# AE722F80F55D5LS_CM55_HE_View register map
Vendor: Alif Semiconductor; Series: E7; File version: 1.0
CPU: CM55 r1p0, selectable endian, MPU, FPU, double-precision FPU, DSP, VTOR, 8 interrupt priority bits, 1 SAU regions
Registers are 32-bit, read-write, reset 0x0 unless marked. A register's access mark holds for its fields unless they carry their own. Offsets are from the block's base; [hi:lo] are bit positions; {n}, {i} and the like mark numbered series.

## LPSPI
Base 0x43000000
Same registers: SPI0 0x48103000, SPI1 0x48104000, SPI2 0x48105000, SPI3 0x48106000
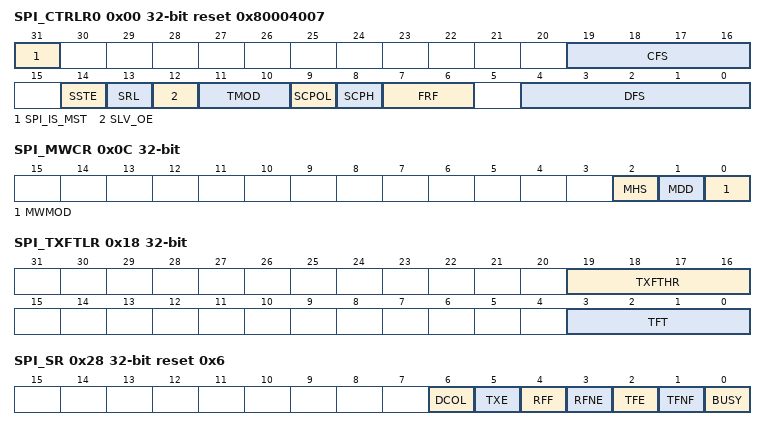
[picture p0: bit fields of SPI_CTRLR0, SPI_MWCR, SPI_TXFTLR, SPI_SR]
0x00 SPI_CTRLR0 reset 0x80004007 — Control Register 0
  [31] SPI_IS_MST — This bit selects if the SPI is working in Master or Slave mode.
    0=SPI is Slave; 1=SPI is Master
  [19:16] CFS — Control Frame Size. Selects the length of the control word for the Microwire frame format.
    {v}={v+1:02}-bit Control Word (v=0..15)
  [14] SSTE — Slave Select Toggle Enable. While operating in SPI mode with clock phase (SCPH) set to 0x0, this bit controls the behavior of the slave select line between data frames.
    0=The slave select line will stay low and SPI_SCLK will run continuously for the duration of the transfer; 1=The slave select line will toggle between consecutive data frames, with the serial clock (SPI_SCLK) being held to its default value while the slave select line is high
  [13] SRL — Shift Register Loop. Used for testing purposes only. When internally active, connects the transmit shift register output to the receive shift register input. Can be used in both serial slave and serial Master mode. When the SPI is configured as a slave in loopback mode, the slave select input and SPI_CLK signals must be provided by an external source. In this mode, the slave cannot generate these signals because there is nothing to which to loop back.
    0=Normal Mode Operation; 1=Test Mode Operation
  [12] SLV_OE — Slave Output Enable. Relevant only when the SPI is configured as a serial slave device. When configured as a serial master, this bit has no functionality. This bit enables or disables the setting of the output enable signal from the SPI serial slave. When the SLV_OE = 0x1, the output enable signal can never be active. When the output enable signal controls the tri-state buffer on the TXD output from the slave, a high impedance state is always present on the slave TXD output when the SLV_OE bit is set to 0x1. This is useful when the master transmits in broadcast mode (master transmits data to all slave devices). Only one slave may respond with data on the master RXD line. This bit is enabled after reset and must be disabled by software (when broadcast mode is used), if the device has no need to respond with data.
    0=Slave output is enabled; 1=Slave output is disabled
  [11:10] TMOD — Transfer Mode. Selects the mode of transfer for serial communication. This field does not affect the transfer duplicity. Only indicates whether the receive or transmit data are valid. In Transmit Only mode, data received from the external device is not valid and is not stored in the receive FIFO memory; it is overwritten on the next transfer. In Receive Only mode, transmitted data are not valid. After the first write to the transmit FIFO, the same word is retransmitted for the duration of the transfer. In Transmit and Receive mode, both transmit and receive data are valid. The transfer continues until the transmit FIFO is empty. Data received from the external device are stored into the receive FIFO memory, where it can be accessed by the host processor.
    0=Transmit and Receive; 1=Transmit Only mode; 2=Receive Only mode; 3=EEPROM Read mode
  [9] SCPOL — Serial Clock Polarity. Valid when the Frame Format (FRF) bit is set to Motorola SPI. Used to select the polarity of the inactive serial clock, which is held inactive when the SPI master is not actively transferring data on the serial bus.
    0=Inactive state of serial clock is low; 1=Inactive state of serial clock is high
  [8] SCPH — Serial Clock Phase. Valid when the FRF bit is set to Motorola SPI. The serial clock phase selects the relationship of the serial clock with the slave select signal. When SCPH = 0, data are captured on the first edge of the serial clock. When SCPH = 1, the serial clock starts toggling one cycle after the slave select line is activated, and data are captured on the second edge of the serial clock.
    0=Serial clock toggles in middle of first bit; 1=Serial clock toggles at start of first bit
  [7:6] FRF — Frame Format. Selects which serial protocol transfers the data.
    0=Motorola SPI frame format; 1=Texas Instruments SSP frame format; 2=National Semiconductors Microwire frame format
  [4:0] DFS — Data Frame Size. Selects the data frame length. When the data frame size is programmed to be less than 32 bits, the receive data is automatically right-justified by the receive logic, with the upper bits of the receive FIFO zero-padded. User must right-justify transmit data before writing into the transmit FIFO. The transmit logic ignores the upper unused bits when transmitting the data.
    {v}={v+1:02}-bit serial data transfer (v=3..31)
0x04 SPI_CTRLR1 — Control Register 1
  [15:0] NDF — Number of Data Frames. When the SPI_CTRLR0[TMOD] = 0x2 or SPI_CTRLR0[TMOD] = 0x3, this bit field sets the number of data frames to be continuously received by the SPI. The SPI continues to receive serial data until the number of data frames received is equal to this register value plus 1, which enables the user to receive up to 64KB of data in a continuous transfer. When the SPI is configured as a serial slave, the transfer continues for as long as the slave is selected. Therefore, this bit field serves no purpose and is not present when the SPI is configured as a serial slave.
0x08 SPI_ENR — SPI Enable Register
  [0] SPI_EN — SPI Enable. Enables and disables all SPI operations. When disabled, all serial transfers are halted immediately. Transmit and receive FIFO buffers are cleared when the device is disabled. It is impossible to program some of the SPI control registers when enabled. When disabled, the SPI sleep output is set (after delay) to inform the system that it is safe to remove the SPI_CLK, thus saving power consumption in the system.
    0=Disables SPI; 1=Enables SPI
0x0C SPI_MWCR — Microwire Control Register
  [2] MHS — Microwire Handshaking. Relevant only when the SPI is configured as a serial master device. When configured as a serial slave, this bit has no functionality. Used to enable and disable the busy/ready handshaking interface for the Microwire protocol. When enabled, the SPI checks for a ready status from the target slave, after the transfer of the last data/control bit, before clearing the BUSY status in the SPI_SR[BUSY] bit.
    0=Handshaking interface is disabled; 1=Handshaking interface is enabled
  [1] MDD — Microwire Control. Defines the direction of the data word when the Microwire serial protocol is used. When this bit is set to 0, the data word is received by the SPI module from the external serial device. When this bit is set to 1, the data word is transmitted from the SPI module to the external serial device.
    0=SPI receives data; 1=SPI transmits data
  [0] MWMOD — Microwire Transfer Mode. Defines whether the Microwire transfer is sequential or non-sequential. When sequential mode is used, only one control word is needed to transmit or receive a block of data words. When non-sequential mode is used, there must be a control word for each data word that is transmitted or received.
    0=Non-Sequential Transfer; 1=Sequential Transfer
0x10 SPI_SER reset 0x1 — Slave Enable Register
  [3:0] SER — Slave Select Enable Flag. Each bit in this bit field corresponds to a slave select line from the SPI master. When a bit in this bit field is set to 0x1, the corresponding slave select line from the master is activated when a serial transfer begins. It should be noted that setting or clearing bits in this bit field have no effect on the corresponding slave select outputs until a transfer is started. Before beginning a transfer, user should enable the bit in this field that corresponds to the slave device with which the master wants to communicate. When not operating in broadcast mode, only one bit in this field should be set.
    0=Not Selected; 1=Selected
0x14 SPI_BAUDR — Baud Rate Select Register
  [15:1] SCKDV — SPI Clock Divider. This field contains the MSB 15 bits of the 16-bit SPI_CLK divider value. The LSB for SPI_CLK divider is always set to 0 and is unaffected by a write operation, which ensures the divider is always set to an even value. If this field is set to all 0s, the serial output clock (SPI_SCLK) is disabled. The frequency of the SPI_SCLK is derived from the following equation: FSPI_SCLK = FSPI_CLK/BAUDR Where BAUDR is any even value between 2 and 65534, and BAUDR = SCKDV x 2. For example, for FSPI_CLK = 3.6864 MHz and SCKDV = 1b'1: BAUDR = 2 and FSPI_SCLK= 3.6864/2 = 1.8432 MHz. For more information, see Section SPI Clock Ratios.
0x18 SPI_TXFTLR — Transmit FIFO Threshold Level Register
  [19:16] TXFTHR — Transfer Start FIFO Level. Used to control the level of entries in transmit FIFO above which transfer will start on serial line. This bit field is used to ensure that sufficient data is present in transmit FIFO before starting a write operation on serial line. These field is valid only for Master mode of operation. Note: This field is functional only for SPI module. It is not functional for LPSPI module.
  [3:0] TFT — Transmit FIFO Threshold. Controls the level of entries (or below) at which the transmit FIFO controller triggers an interrupt. The FIFO depth is 16. If the value in this bit field is set greater than or equal to the depth of the FIFO, this bit field is not written and retains its current value. When the number of transmit FIFO entries is less than or equal to this value, the transmit FIFO empty interrupt is triggered.
0x1C SPI_RXFTLR — Receive FIFO Threshold Level Register
  [3:0] RFT — Receive FIFO Threshold. Controls the level of entries (or above) at which the receive FIFO controller triggers an interrupt. The FIFO depth is 16. If the value in this bit field is set greater than the depth of the FIFO, this bit field is not written and retains its current value. When the number of receive FIFO entries is greater than or equal to this value + 1, the receive FIFO full interrupt is triggered.
0x20 SPI_TXFLR ro — Transmit FIFO Level Register
  [4:0] TXTFL — Transmit FIFO Level. Contains the number of valid data entries in the transmit FIFO.
0x24 SPI_RXFLR ro — Receive FIFO Level Register
  [4:0] RXTFL — Receive FIFO Level. Contains the number of valid data entries in the receive FIFO.
0x28 SPI_SR ro reset 0x6 — Status Register
  [6] DCOL — Data Collision Error. Relevant only when the SPI is configured as a master device. This bit is set if slave select input is asserted by other master, when the SPI master is in the middle of the transfer. This informs the processor that the last data transfer was halted before completion. This bit is cleared when read.
    0=No Error; 1=Transmit Data Collision Error
  [5] TXE — Transmission Error. Set if the transmit FIFO is empty when a transfer is started. This bit can be set only when the SPI is configured as a slave device. Note: LPSPI supports Master mode only. The high-speed SPIs support Master and Slave modes. For more information, see Section SPI Overview. Data from the previous transmission is present on the TXD line. This bit is cleared when read.
    0=No Error; 1=Transmission Error
  [4] RFF — Receive FIFO Full. When the receive FIFO is completely full, this bit is set. When the receive FIFO contains one or more empty location, this bit is cleared.
    0=Receive FIFO is not full; 1=Receive FIFO is full
  [3] RFNE — Receive FIFO Not Empty. Set when the receive FIFO contains one or more entries and is cleared when the receive FIFO is empty. This bit can be polled by software to completely empty the receive FIFO.
    0=Receive FIFO is empty; 1=Receive FIFO is not empty
  [2] TFE — Transmit FIFO Empty. When the transmit FIFO is completely empty, this bit is set. When the transmit FIFO contains one or more valid entries, this bit is cleared. This bit field does not request an interrupt.
    0=Transmit FIFO is not empty; 1=Transmit FIFO is empty
  [1] TFNF — Transmit FIFO Not Full. Set when the transmit FIFO contains one or more empty locations, and is cleared when the FIFO is full.
    0=Transmit FIFO is full; 1=Transmit FIFO is not full
  [0] BUSY — SPI Busy Flag. When set, indicates that a serial transfer is in progress; when cleared indicates that the SPI is idle or disabled.
    0=SPI is idle or disabled; 1=SPI is actively transferring data
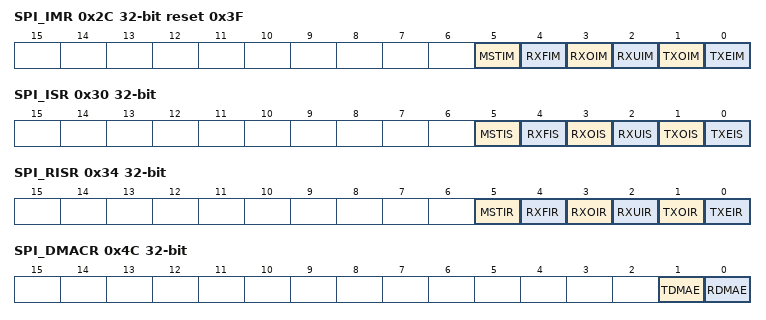
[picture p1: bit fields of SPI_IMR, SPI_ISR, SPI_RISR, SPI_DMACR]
0x2C SPI_IMR reset 0x3F — Interrupt Mask Register
  [5] MSTIM — Multi-Master Contention Interrupt Mask. This bit is not present if the SPI is configured as a serial master device.
    0=Multi-Master Contention interrupt is masked; 1=Multi-Master Contention interrupt is not masked
  [4] RXFIM — Receive FIFO Full Interrupt Mask.
    0=Receive FIFO Full interrupt is masked; 1=Receive FIFO Full interrupt is not masked
  [3] RXOIM — Receive FIFO Overflow Interrupt Mask.
    0=Receive FIFO Overflow interrupt is masked; 1=Receive FIFO Overflow interrupt is not masked
  [2] RXUIM — Receive FIFO Underflow Interrupt Mask.
    0=Receive FIFO Underflow interrupt is masked; 1=Receive FIFO Underflow interrupt is not masked
  [1] TXOIM — Transmit FIFO Overflow Interrupt Mask.
    0=Transmit FIFO Overflow interrupt is masked; 1=Transmit FIFO Overflow interrupt is not masked
  [0] TXEIM — Transmit FIFO Empty Interrupt Mask.
    0=Transmit FIFO Empty interrupt is masked; 1=Transmit FIFO Empty interrupt is not masked
0x30 SPI_ISR ro — Interrupt Status Register
  [5] MSTIS — Multi-Master Contention Interrupt Status. This bit is not present if the SPI is configured as a serial slave device.
    0=Multi-Master Contention interrupt is not active after masking; 1=Multi-Master Contention interrupt is active after masking
  [4] RXFIS — Receive FIFO Full Interrupt Status.
    0=Receive FIFO Full interrupt is not active after masking; 1=Receive FIFO Full interrupt is active after masking
  [3] RXOIS — Receive FIFO Overflow Interrupt Status.
    0=Receive FIFO Overflow interrupt is not active after masking; 1=Receive FIFO Overflow interrupt is active after masking
  [2] RXUIS — Receive FIFO Underflow Interrupt Status.
    0=Receive FIFO Underflow interrupt is not active after masking; 1=Receive FIFO Underflow interrupt is active after masking
  [1] TXOIS — Transmit FIFO Overflow Interrupt Status.
    0=Transmit FIFO Overflow interrupt is not active after masking; 1=Transmit FIFO Overflow interrupt is active after masking
  [0] TXEIS — Transmit FIFO Empty Interrupt Status.
    0=Transmit FIFO Empty interrupt is not active after masking; 1=Transmit FIFO Empty interrupt is active after masking
0x34 SPI_RISR ro — Raw Interrupt Status Register
  [5] MSTIR — Multi-Master Contention Raw Interrupt Status. This bit field is not present if the SPI is configured as a serial slave device.
    0=Multi-Master Contention interrupt is not active prior masking; 1=Multi-Master Contention interrupt is active prior to masking
  [4] RXFIR — Receive FIFO Full Raw Interrupt Status.
    0=Receive FIFO Full interrupt is not active prior masking; 1=Receive FIFO Full interrupt is active prior to masking
  [3] RXOIR — Receive FIFO Overflow Raw Interrupt Status.
    0=Receive FIFO Overflow interrupt is not active prior masking; 1=Receive FIFO Overflow interrupt is active prior to masking
  [2] RXUIR — Receive FIFO Underflow Raw Interrupt Status.
    0=Receive FIFO Underflow interrupt is not active prior masking; 1=Receive FIFO Underflow interrupt is active prior to masking
  [1] TXOIR — Transmit FIFO Overflow Raw Interrupt Status.
    0=Transmit FIFO Overflow interrupt is not active prior masking; 1=Transmit FIFO Overflow interrupt is active prior to masking
  [0] TXEIR — Transmit FIFO Empty Raw Interrupt Status.
    0=Transmit FIFO Empty interrupt is not active prior masking; 1=Transmit FIFO Empty interrupt is active prior to masking
0x38 SPI_TXOICR ro — Transmit FIFO Overflow Interrupt Clear Register
  [0] TXOICR — Clear Transmit FIFO Overflow Interrupt. This bit reflects the status of the interrupt. A read from this bit clears the Transmit FIFO Overflow interrupt; writing has no effect.
0x3C SPI_RXOICR ro — Receive FIFO Overflow Interrupt Clear Register
  [0] RXOICR — Clear Receive FIFO Overflow Interrupt. This bit reflects the status of the interrupt. A read from this bit clears the Receive FIFO Overflow interrupt; writing has no effect.
0x40 SPI_RXUICR ro — Receive FIFO Underflow Interrupt Clear Register
  [0] RXUICR — Clear Receive FIFO Underflow Interrupt. This bit reflects the status of the interrupt. A read from this bit clears the Receive FIFO Underflow interrupt; writing has no effect.
0x44 SPI_MSTICR ro — Multi-Master Interrupt Clear Register
  [0] MSTICR — Clear Multi-Master Contention Interrupt. This bit reflects the status of the interrupt. A read from this bit clears the Multi-Master Contention interrupt; writing has no effect.
0x48 SPI_ICR ro — Interrupt Clear Register
  [0] ICR — Clear Interrupts. This bit is set if any of the interrupts below are active. A read clears the Transmit FIFO Overflow, Receive FIFO Underflow, Receive FIFO Overflow, and Multi-Master Contention interrupts. Writing to this bit has no effect.
0x4C SPI_DMACR — DMA Control Register
  [1] TDMAE — Transmit DMA Enable. This bit enables/disables the transmit FIFO DMA channel.
    0=Transmit DMA disabled; 1=Transmit DMA enabled
  [0] RDMAE — Receive DMA Enable. This bit enables/disables the receive FIFO DMA channel.
    0=Receive DMA disabled; 1=Receive DMA enabled
0x50 SPI_DMATDLR — DMA Transmit Data Level Register
  [3:0] DMATDL — Transmit Data Level. This bit field controls the level at which a DMA request is made by the transmit logic. It is equal to the watermark level; that is, the transmit DMA request signal is generated when the number of valid data entries in the transmit FIFO is equal to or below this bit field value, and the SPI_DMACR[TDMAE] = 0x1.
0x54 SPI_DMARDLR — DMA Receive Data Level Register
  [3:0] DMARDL — Receive Data Level. This bit field controls the level at which a DMA request is made by the receive logic. The watermark level is equal to DMARDL + 1; that is, receive DMA request is generated when the number of valid data entries in the receive FIFO is equal to or above this bit field value + 1, and SPI_DMACR[RDMAE] = 0x1.
0x58 SPI_IDR ro reset 0xC7C5C3C1 — Reserved
  [31:0] IDCODE — Reserved.
0x5C SPI_VERSION_ID ro reset 0x3130322A — Reserved
  [31:0] SPI_COMP_VERSION — Reserved.
{0x60+4i} SPI_DR[{i}] (i=0..35) — SPI Data Register (n)
  [31:0] DR — Data Register (n). When writing to this register, the user must right-justify the data. Read data are automatically right-justified. Read = Receive FIFO buffer Write = Transmit FIFO buffer
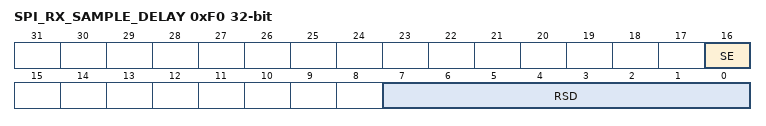
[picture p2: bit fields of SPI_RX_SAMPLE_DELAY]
0xF0 SPI_RX_SAMPLE_DELAY — RX Sample Delay Register
  [16] SE ro — Receive Data Sampling Edge. This bit is used to decide the sampling edge for RXD signal with SPI_CLK. Then this bit is set to 1 then negative edge of SPI_CLK will be used to sample the incoming data, otherwise positive edge will be used for sampling.
  [7:0] RSD — Receive Data Sample Delay. This bit field is used to delay the sample of the RXD input port. Each value represents a single SPI_CLK delay on the sample of RXD. Note: If this bit field is programmed with a value that exceeds the depth of the internal shift registers (internal shift register depth = 4) zero delay will be applied to the RXD sample.
